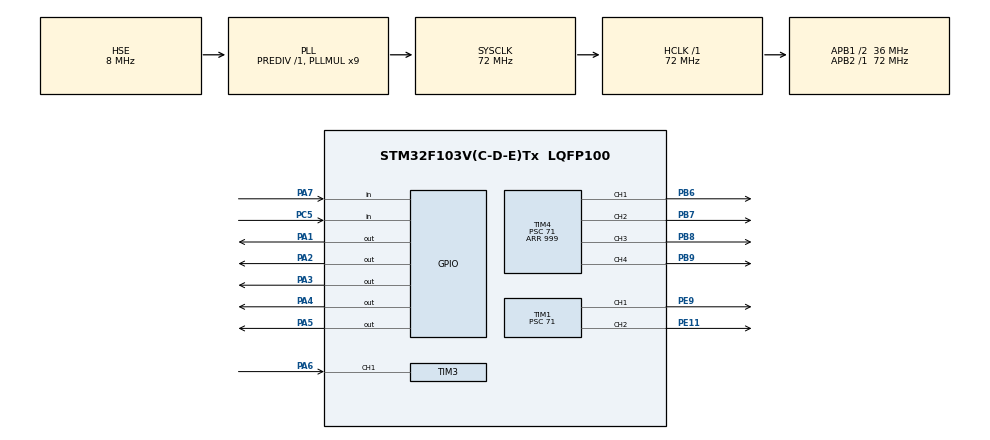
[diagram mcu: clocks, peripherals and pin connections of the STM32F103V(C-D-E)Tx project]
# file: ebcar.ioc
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FREERTOS.Tasks01=detc_task,48,128,detctask,As weak,NULL,Dynamic,NULL,NULL;run_task,24,128,runtask,As weak,NULL,Dynamic,NULL,NULL
Mcu.Family=STM32F1
Mcu.Name=STM32F103V(C-D-E)Tx
Mcu.Package=LQFP100
NVIC.PriorityGroup=NVIC_PRIORITYGROUP_4
NVIC.TIM3_IRQn=true\:5\:0\:false\:false\:true\:true\:true\:true\:true
OSC_IN.Mode=HSE-External-Oscillator
OSC_IN.Signal=RCC_OSC_IN
OSC_OUT.Mode=HSE-External-Oscillator
OSC_OUT.Signal=RCC_OSC_OUT
PA1.GPIO_PuPd=GPIO_PULLUP
PA1.PinState=GPIO_PIN_SET
PA1.Signal=GPIO_Output
PA13.Mode=Serial_Wire
PA13.Signal=SYS_JTMS-SWDIO
PA14.Mode=Serial_Wire
PA14.Signal=SYS_JTCK-SWCLK
PA2.GPIO_PuPd=GPIO_PULLUP
PA2.PinState=GPIO_PIN_SET
PA2.Signal=GPIO_Output
PA3.GPIO_PuPd=GPIO_PULLUP
PA3.PinState=GPIO_PIN_SET
PA3.Signal=GPIO_Output
PA4.GPIO_PuPd=GPIO_PULLUP
PA4.PinState=GPIO_PIN_SET
PA4.Signal=GPIO_Output
PA5.GPIO_PuPd=GPIO_PULLUP
PA5.PinState=GPIO_PIN_SET
PA5.Signal=GPIO_Output
PA6.Signal=S_TIM3_CH1
PA7.GPIO_PuPd=GPIO_PULLUP
PA7.Signal=GPIO_Input
PB6.Signal=S_TIM4_CH1
PB7.Signal=S_TIM4_CH2
PB8.Signal=S_TIM4_CH3
PB9.Signal=S_TIM4_CH4
PC5.GPIO_PuPd=GPIO_PULLUP
PC5.Signal=GPIO_Input
PE11.Signal=S_TIM1_CH2
PE9.Signal=S_TIM1_CH1
ProjectManager.HeapSize=0x200
ProjectManager.StackSize=0x400
ProjectManager.TargetToolchain=MDK-ARM V5.32
RCC.AHBFreq_Value=72000000
RCC.APB1CLKDivider=RCC_HCLK_DIV2
RCC.APB1Freq_Value=36000000
RCC.APB1TimFreq_Value=72000000
RCC.APB2Freq_Value=72000000
RCC.APB2TimFreq_Value=72000000
RCC.HCLKFreq_Value=72000000
RCC.PLLMUL=RCC_PLL_MUL9
RCC.PLLSourceVirtual=RCC_PLLSOURCE_HSE
RCC.SYSCLKFreq_VALUE=72000000
RCC.SYSCLKSource=RCC_SYSCLKSOURCE_PLLCLK
RCC.USBFreq_Value=72000000
SH.S_TIM1_CH1.0=TIM1_CH1,PWM Generation1 CH1
SH.S_TIM1_CH2.0=TIM1_CH2,PWM Generation2 CH2
SH.S_TIM3_CH1.0=TIM3_CH1,Input_Capture1_from_TI1
SH.S_TIM4_CH1.0=TIM4_CH1,PWM Generation1 CH1
SH.S_TIM4_CH2.0=TIM4_CH2,PWM Generation2 CH2
SH.S_TIM4_CH3.0=TIM4_CH3,PWM Generation3 CH3
SH.S_TIM4_CH4.0=TIM4_CH4,PWM Generation4 CH4
TIM1.Channel-PWM\ Generation1\ CH1=TIM_CHANNEL_1
TIM1.Channel-PWM\ Generation2\ CH2=TIM_CHANNEL_2
TIM1.Period=999
TIM1.Prescaler=71
TIM3.Channel-Input_Capture1_from_TI1=TIM_CHANNEL_1
TIM3.Period=0xffff
TIM3.Prescaler=72-1
TIM4.Channel-PWM\ Generation1\ CH1=TIM_CHANNEL_1
TIM4.Channel-PWM\ Generation2\ CH2=TIM_CHANNEL_2
TIM4.Channel-PWM\ Generation3\ CH3=TIM_CHANNEL_3
TIM4.Channel-PWM\ Generation4\ CH4=TIM_CHANNEL_4
TIM4.OCPolarity_1=TIM_OCPOLARITY_HIGH
TIM4.OCPolarity_2=TIM_OCPOLARITY_HIGH
TIM4.OCPolarity_3=TIM_OCPOLARITY_HIGH
TIM4.OCPolarity_4=TIM_OCPOLARITY_HIGH
TIM4.Period=999
TIM4.Prescaler=71
VP_FREERTOS_VS_CMSIS_V2.Mode=CMSIS_V2
board=custom

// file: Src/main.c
/* USER CODE BEGIN Header */
/**
  ******************************************************************************
  * @file           : main.c
  * @brief          : Main program body
  ******************************************************************************
  * @attention
  *
  * Copyright (c) 2022 STMicroelectronics.
  * All rights reserved.
  *
  * This software is licensed under terms that can be found in the LICENSE file
  * in the root directory of this software component.
  * If no LICENSE file comes with this software, it is provided AS-IS.
  *
  ******************************************************************************
  */
/* USER CODE END Header */
#include "main.h"
#include "cmsis_os.h"
#include "tim.h"
#include "gpio.h"

void SystemClock_Config(void);
void MX_FREERTOS_Init(void);

int main(void)
{

  /* MCU Configuration--------------------------------------------------------*/

  /* Reset of all peripherals, Initializes the Flash interface and the Systick. */
  HAL_Init();

  /* Configure the system clock */
  SystemClock_Config();

  /* Initialize all configured peripherals */
  MX_GPIO_Init();
  MX_TIM1_Init();
  MX_TIM3_Init();
  MX_TIM4_Init();
  /* USER CODE BEGIN 2 */
  mot_init();
  usdev_init();
  /* USER CODE END 2 */

  /* Init scheduler */
  osKernelInitialize();  /* Call init function for freertos objects (in freertos.c) */
  MX_FREERTOS_Init();

  /* Start scheduler */
  osKernelStart();

  /* We should never get here as control is now taken by the scheduler */
  /* Infinite loop */
  while (1)
  {

  }
}

void SystemClock_Config(void)
{
  RCC_OscInitTypeDef RCC_OscInitStruct = {0};
  RCC_ClkInitTypeDef RCC_ClkInitStruct = {0};

  /** Initializes the RCC Oscillators according to the specified parameters
  * in the RCC_OscInitTypeDef structure.
  */
  RCC_OscInitStruct.OscillatorType = RCC_OSCILLATORTYPE_HSE;
  RCC_OscInitStruct.HSEState = RCC_HSE_ON;
  RCC_OscInitStruct.HSEPredivValue = RCC_HSE_PREDIV_DIV1;
  RCC_OscInitStruct.HSIState = RCC_HSI_ON;
  RCC_OscInitStruct.PLL.PLLState = RCC_PLL_ON;
  RCC_OscInitStruct.PLL.PLLSource = RCC_PLLSOURCE_HSE;
  RCC_OscInitStruct.PLL.PLLMUL = RCC_PLL_MUL9;
  if (HAL_RCC_OscConfig(&RCC_OscInitStruct) != HAL_OK)
  {
    Error_Handler();
  }

  /** Initializes the CPU, AHB and APB buses clocks
  */
  RCC_ClkInitStruct.ClockType = RCC_CLOCKTYPE_HCLK|RCC_CLOCKTYPE_SYSCLK
                              |RCC_CLOCKTYPE_PCLK1|RCC_CLOCKTYPE_PCLK2;
  RCC_ClkInitStruct.SYSCLKSource = RCC_SYSCLKSOURCE_PLLCLK;
  RCC_ClkInitStruct.AHBCLKDivider = RCC_SYSCLK_DIV1;
  RCC_ClkInitStruct.APB1CLKDivider = RCC_HCLK_DIV2;
  RCC_ClkInitStruct.APB2CLKDivider = RCC_HCLK_DIV1;

  if (HAL_RCC_ClockConfig(&RCC_ClkInitStruct, FLASH_LATENCY_2) != HAL_OK)
  {
    Error_Handler();
  }
}

void Error_Handler(void)
{
  __disable_irq();
  while (1)
  {
  }
}

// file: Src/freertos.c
/* USER CODE BEGIN Header */
/**
  ******************************************************************************
  * File Name          : freertos.c
  * Description        : Code for freertos applications
  ******************************************************************************
  * @attention
  *
  * Copyright (c) 2022 STMicroelectronics.
  * All rights reserved.
  *
  * This software is licensed under terms that can be found in the LICENSE file
  * in the root directory of this software component.
  * If no LICENSE file comes with this software, it is provided AS-IS.
  *
  ******************************************************************************
  */
/* USER CODE END Header */

#include "FreeRTOS.h"
#include "task.h"
#include "main.h"
#include "cmsis_os.h"

/* Definitions for detc_task */
osThreadId_t detc_taskHandle;
const osThreadAttr_t detc_task_attributes = {
  .name = "detc_task",
  .stack_size = 128 * 4,
  .priority = (osPriority_t) osPriorityRealtime,
};
/* Definitions for run_task */
osThreadId_t run_taskHandle;
const osThreadAttr_t run_task_attributes = {
  .name = "run_task",
  .stack_size = 128 * 4,
  .priority = (osPriority_t) osPriorityNormal,
};

void detctask(void *argument);
void runtask(void *argument);

void MX_FREERTOS_Init(void); /* (MISRA C 2004 rule 8.1) */

void MX_FREERTOS_Init(void) {

  /* Create the thread(s) */
  /* creation of detc_task */
  detc_taskHandle = osThreadNew(detctask, NULL, &detc_task_attributes);

  /* creation of run_task */
  run_taskHandle = osThreadNew(runtask, NULL, &run_task_attributes);

}

__weak void detctask(void *argument)
{
  for(;;)
  {
    osDelay(1);
  }
}

__weak void runtask(void *argument)
{
  for(;;)
  {
    osDelay(1);
  }
}
